# FU540 register map
Vendor: SiFive; File version: 1.0
SiFive Freedom U540 64-bit RISC-V CPU
Registers are 32-bit, read-write, no defined reset value unless marked. A register's access mark holds for its fields unless they carry their own. Offsets are from the block's base; lines under a group give offsets from that group; [hi:lo] are bit positions; {n}, {i} and the like mark numbered series; 'fields as' and 'values as' point back to an identical list; <NAME> marks a mode.

## Memory map
0x00001000 MSEL — Mode Select
0x10000000 PRCI — PRCI (Power Reset Clocking Interrupt) Block
0x10010000 UART0 — Universal Asynchronous Receiver Transmitter 0
0x10011000 UART1 — Universal Asynchronous Receiver Transmitter 1

## MSEL — Mode Select
Base 0x00001000
0x00 MSEL — The MSEL pin state
  [3:0] MSEL ro

## PRCI — PRCI (Power Reset Clocking Interrupt) Block
Base 0x10000000
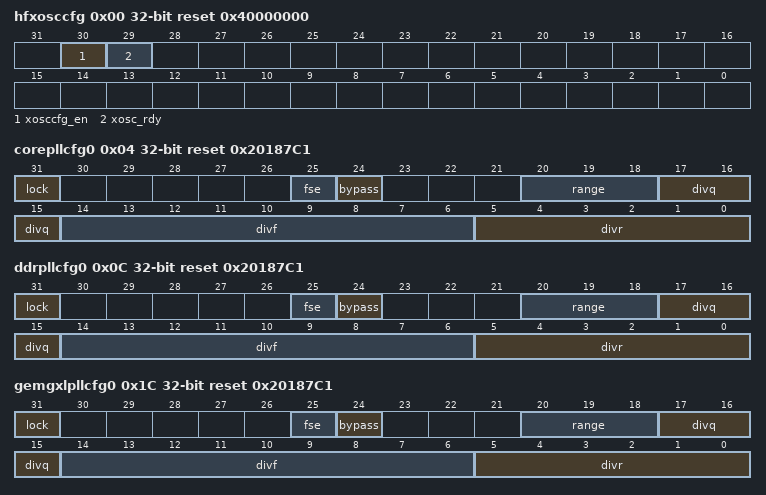
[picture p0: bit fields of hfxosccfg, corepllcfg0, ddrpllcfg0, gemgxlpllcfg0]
0x00 hfxosccfg reset 0x40000000 — Crystal Input Control Register
  [30] xosccfg_en — Crystal input enable
  [29] xosc_rdy — Crystal input ready
0x04 corepllcfg0 reset 0x20187C1 — Core PLL Configuration Register
  [31] lock — PLL locked
  [25] fse — Internal or external input path. Valid setting is 1, internal feedback.
  [24] bypass — PLL bypass
  [20:18] range — PLL filter range. 3'b100 = 33MHz
  [17:15] divq — Log2 of PLL output divider. Valid settings are 1, 2, 3, 4, 5, 6
  [14:6] divf — PLL feedback divider value minus one
  [5:0] divr — PLL reference divider value minus one
0x0C ddrpllcfg0 reset 0x20187C1 — DDR PLL Configuration Register
  [31] lock — PLL locked
  [25] fse — Internal or external input path. Valid settings is 1, internal feedback.
  [24] bypass — PLL bypass
  [20:18] range — PLL filter range. 3'b100 = 33MHz
  [17:15] divq — Log2 of PLL output divider. Valid settings are 1,2,3,4,5,6
  [14:6] divf — PLL feedback divider value minus one
  [5:0] divr — PLL reference divider value minus one
0x10 ddrpllcfg1 reset 0x0 — DDR PLL Configuration Register
  [24] cke — PLL clock output enable. Glitch free clock gate after PLL output. 1 enables clock, 0 disables clock
0x1C gemgxlpllcfg0 reset 0x20187C1 — Gigabit Ethernet PLL Configuration Register
  fields as ddrpllcfg0
0x20 gemgxlpllcfg1 reset 0x0 — Gigabit Ethernet PLL Configuration Register
  fields as ddrpllcfg1
0x24 coreclksel reset 0x1 — CORECLK Source Selection Register
  [0] coreclksel — CORECLK select. 0 = CORE_PLL output 1 = HFCLK
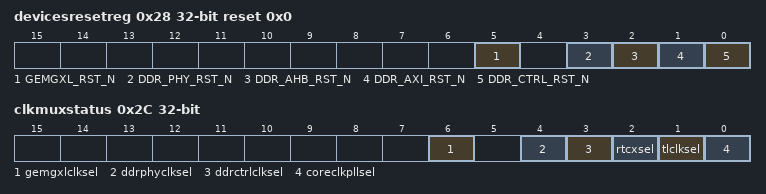
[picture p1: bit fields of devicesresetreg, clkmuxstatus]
0x28 devicesresetreg reset 0x0 — Peripheral Devices Reset Control Register
  [5] GEMGXL_RST_N — Gigabit Ethernet Subsystem reset (active low)
  [3] DDR_PHY_RST_N — DDR PHY reset (active low)
  [2] DDR_AHB_RST_N — DDR Controller AHB interface reset (active low)
  [1] DDR_AXI_RST_N — DDR Controller AXI interface reset (active low)
  [0] DDR_CTRL_RST_N — DDR Controller reset (active low)
0x2C clkmuxstatus
  [6] gemgxlclksel, [4] ddrphyclksel, [3] ddrctrlclksel, [2] rtcxsel, [1] tlclksel, [0] coreclkpllsel
0xF0 procmoncfg — PROCMON Configuration Register
  [24] coreclksel — Select CORECLK

## UART0 — Universal Asynchronous Receiver Transmitter 0
Base 0x10010000
Same registers: UART1 0x10011000
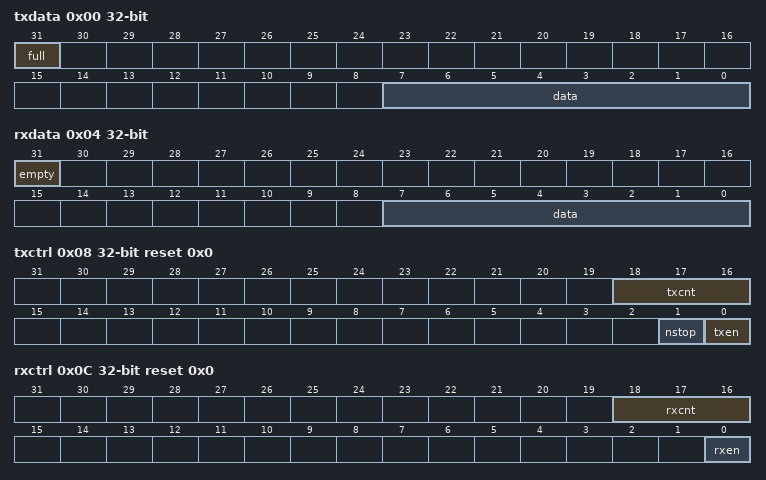
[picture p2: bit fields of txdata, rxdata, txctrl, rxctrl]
0x00 txdata — Transmit Data Register
  [31] full — Transmit FIFO full
  [7:0] data — Transmit data
0x04 rxdata — Receive Data Register
  [31] empty — Receive FIFO empty
  [7:0] data — Received data
0x08 txctrl reset 0x0 — Transmit Control Register
  [18:16] txcnt — Transmit watermark level
  [1] nstop — Number of stop bits
  [0] txen — Transmit enable
0x0C rxctrl reset 0x0 — Receive Control Register
  [18:16] rxcnt — Receive watermark level
  [0] rxen — Receive enable
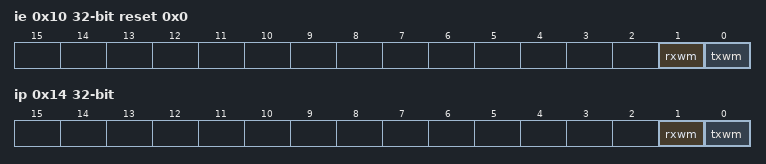
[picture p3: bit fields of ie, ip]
0x10 ie reset 0x0 — Interrupt Enable Register
  [1] rxwm — Receive watermark interrupt enable
  [0] txwm — Transmit watermark interrupt enable
0x14 ip — Interrupt Pending Register
  [1] rxwm — Receive watermark interrupt pending
  [0] txwm — Transmit watermark interrupt pending
0x18 div reset 0x121 — Baud Rate Divisor Register
  [19:0] div — Baud rate divisor
